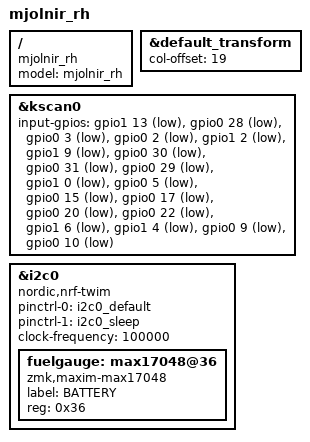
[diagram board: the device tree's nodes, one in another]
#include "mjolnir.dtsi"
#include "mjolnir_rh-pinctrl.dtsi"


/ {
    model = "mjolnir_rh";
    compatible = "mjolnir_rh";

};

/* For right hand, the columns are offset by 19 */
&default_transform {
    col-offset = <19>;
};

&kscan0 {
    input-gpios
    = <&gpio1 13 (GPIO_ACTIVE_LOW | GPIO_PULL_UP)> // 0_0
    , <&gpio0 28 (GPIO_ACTIVE_LOW | GPIO_PULL_UP)> // 1_0
    , <&gpio0  3 (GPIO_ACTIVE_LOW | GPIO_PULL_UP)> // 2_0
    , <&gpio0  2 (GPIO_ACTIVE_LOW | GPIO_PULL_UP)> // 3_0
    , <&gpio1  2 (GPIO_ACTIVE_LOW | GPIO_PULL_UP)> // 4_0
    , <&gpio1  9 (GPIO_ACTIVE_LOW | GPIO_PULL_UP)> // 0_1
    , <&gpio0 30 (GPIO_ACTIVE_LOW | GPIO_PULL_UP)> // 1_1
    , <&gpio0 31 (GPIO_ACTIVE_LOW | GPIO_PULL_UP)> // 2_1
    , <&gpio0 29 (GPIO_ACTIVE_LOW | GPIO_PULL_UP)> // 3_1
    , <&gpio1  0 (GPIO_ACTIVE_LOW | GPIO_PULL_UP)> // 4_1
    , <&gpio0  5 (GPIO_ACTIVE_LOW | GPIO_PULL_UP)> // 0_2
    , <&gpio0 15 (GPIO_ACTIVE_LOW | GPIO_PULL_UP)> // 1_2
    , <&gpio0 17 (GPIO_ACTIVE_LOW | GPIO_PULL_UP)> // 2_2
    , <&gpio0 20 (GPIO_ACTIVE_LOW | GPIO_PULL_UP)> // 3_2
    , <&gpio0 22 (GPIO_ACTIVE_LOW | GPIO_PULL_UP)> // 4_2
    , <&gpio1  6 (GPIO_ACTIVE_LOW | GPIO_PULL_UP)> // 1_3
    , <&gpio1  4 (GPIO_ACTIVE_LOW | GPIO_PULL_UP)> // 2_3
    , <&gpio0  9 (GPIO_ACTIVE_LOW | GPIO_PULL_UP)> // 3_3
    , <&gpio0 10 (GPIO_ACTIVE_LOW | GPIO_PULL_UP)> // 4_3
    ;
};

&i2c0 {
	status = "okay";
	compatible = "nordic,nrf-twim";
	pinctrl-0 = <&i2c0_default>;
    pinctrl-1 = <&i2c0_sleep>;
    pinctrl-names = "default", "sleep";
	clock-frequency = <100000>;

	fuelgauge: max17048@36 {
		compatible = "zmk,maxim-max17048";
		label = "BATTERY";
		reg = <0x36>;
	};
};
